VERSION "Nissan Sentra broadcast and body-control signals"

NS_ :

BS_:

BU_: BCM XXX Vector__XXX

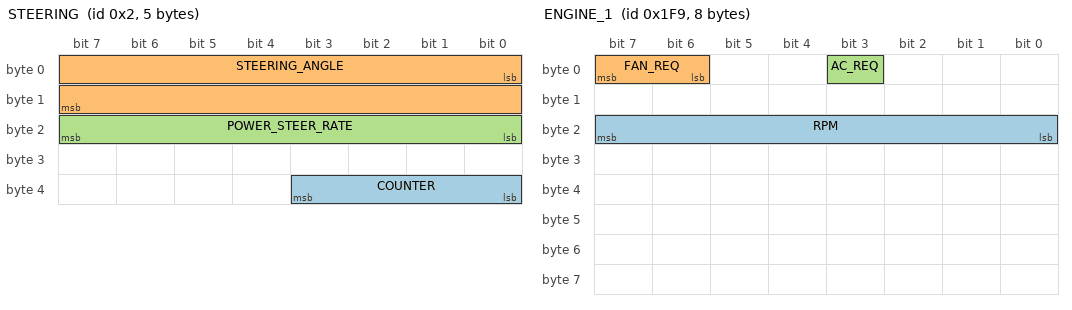
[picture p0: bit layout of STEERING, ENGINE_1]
BO_ 2 STEERING: 5 XXX
 SG_ COUNTER : 35|4@0+ (1,0) [0|255] "" XXX
 SG_ STEERING_ANGLE : 0|16@1- (0.1,0) [0|65535] "deg" XXX
 SG_ POWER_STEER_RATE : 23|8@0+ (1,0) [0|255] "" XXX

BO_ 505 ENGINE_1: 8 XXX
 SG_ RPM : 16|8@1+ (34.8837,0) [0|45000] "R/min" XXX
 SG_ FAN_REQ : 6|2@1+ (1,0) [0|3] "" XXX
 SG_ AC_REQ : 3|1@1+ (1,0) [0|1] "" XXX

BO_ 561 ENGINE_2: 8 XXX
 SG_ PEDAL_POSITION_ENGINE_2 : 16|8@1+ (0.5,0) [0|200] "%" XXX

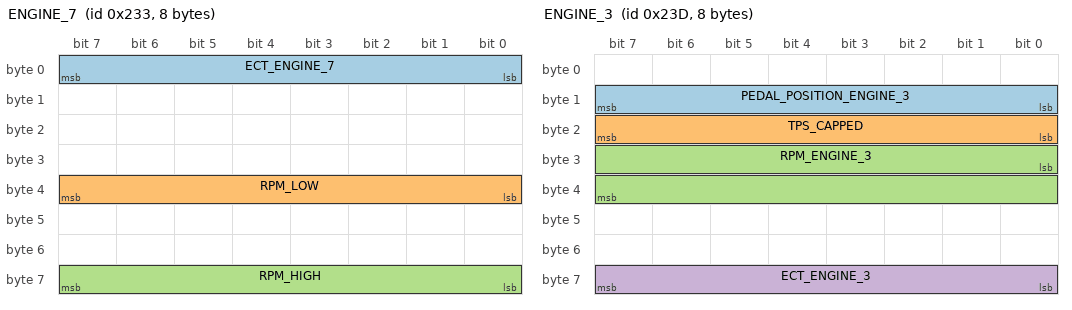
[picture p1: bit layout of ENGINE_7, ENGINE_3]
BO_ 563 ENGINE_7: 8 XXX
 SG_ ECT_ENGINE_7 : 0|8@1+ (0.366666,0) [0|255] "C" XXX
 SG_ RPM_LOW : 32|8@1+ (3.15,0) [0|45000] "R/min" XXX
 SG_ RPM_HIGH : 56|8@1+ (3.15,0) [0|45000] "R/min" XXX

BO_ 573 ENGINE_3: 8 XXX
 SG_ PEDAL_POSITION_ENGINE_3 : 8|8@1+ (0.392,0) [0|255] "%" XXX
 SG_ TPS_CAPPED : 16|8@1+ (0.392,0) [0|255] "%" XXX
 SG_ RPM_ENGINE_3 : 24|16@1+ (3.15,0) [0|45000] "R/min" XXX
 SG_ ECT_ENGINE_3 : 56|8@1+ (0.366666,0) [0|255] "C" XXX

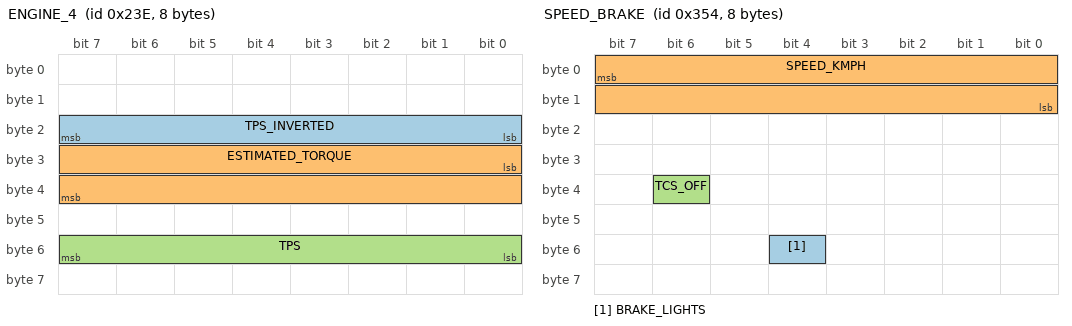
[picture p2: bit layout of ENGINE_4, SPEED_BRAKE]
BO_ 574 ENGINE_4: 8 XXX
 SG_ TPS_INVERTED : 16|8@1+ (0.392,0) [0|255] "%" XXX
 SG_ ESTIMATED_TORQUE : 24|16@1+ (0.1,0) [0|45000] "Nm" XXX
 SG_ TPS : 48|8@1+ (0.392,0) [0|255] "%" XXX

BO_ 595 TCU_1: 8 XXX
 SG_ SHAFT_1_SPEED : 32|16@1+ (1,0) [0|45000] "r/min" XXX
 SG_ SHAFT_2_SPEED : 48|16@1+ (1,0) [0|45000] "r/min" XXX

BO_ 640 SPEED: 8 XXX
 SG_ SPEED : 32|16@1+ (0.01,0) [0|45000] "km/h" XXX

BO_ 644 ABS_1: 8 XXX
 SG_ WHEEL_1_SPEED : 0|16@1+ (0.01,0) [0|45000] "km/h" XXX
 SG_ WHEEL_2_SPEED : 15|16@1+ (0.01,0) [0|45000] "km/h" XXX

BO_ 645 ABS_2: 8 XXX
 SG_ WHEEL_3_SPEED : 0|16@1+ (0.01,0) [0|45000] "km/h" XXX
 SG_ WHEEL_4_SPEED : 15|16@1+ (0.01,0) [0|45000] "km/h" XXX

BO_ 852 SPEED_BRAKE: 8 XXX
 SG_ BRAKE_LIGHTS : 52|1@0+ (1,0) [0|1] "" XXX
 SG_ SPEED_KMPH : 7|16@0+ (0.010176,0) [0|101348.4544] "km/h" XXX
 SG_ TCS_OFF : 38|1@0+ (1,0) [0|1] "" XXX

BO_ 861 BCM: 8 XXX

BO_ 1361 ENGINE_5: 8 XXX
 SG_ ECT : 0|8@1+ (1,-45) [-45|150] "C" XXX

BO_ 1408 ENGINE_6: 8 XXX
 SG_ RPM_ENGINE_6 : 7|16@0+ (1.5,0) [0|65535] "" XXX
 SG_ OIL_TEMP : 32|8@1+ (1,-40) [-40|150] "C" XXX

BO_ 1477 MILEAGE: 8 XXX

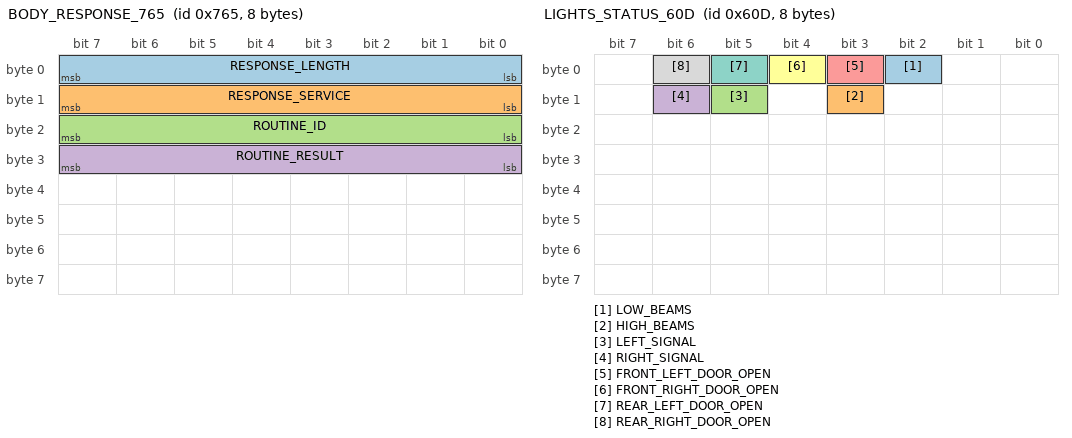
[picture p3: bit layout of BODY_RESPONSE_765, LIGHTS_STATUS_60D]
BO_ 1893 BODY_RESPONSE_765: 8 BCM
 SG_ RESPONSE_LENGTH : 0|8@1+ (1,0) [0|8] "" Vector__XXX
 SG_ RESPONSE_SERVICE : 8|8@1+ (1,0) [0|255] "" Vector__XXX
 SG_ ROUTINE_ID : 16|8@1+ (1,0) [0|255] "" Vector__XXX
 SG_ ROUTINE_RESULT : 24|8@1+ (1,0) [0|255] "" Vector__XXX

BO_ 1549 LIGHTS_STATUS_60D: 8 BCM
 SG_ LOW_BEAMS : 2|1@1+ (1,0) [0|1] "" Vector__XXX
 SG_ HIGH_BEAMS : 11|1@1+ (1,0) [0|1] "" Vector__XXX
 SG_ LEFT_SIGNAL : 13|1@1+ (1,0) [0|1] "" Vector__XXX
 SG_ RIGHT_SIGNAL : 14|1@1+ (1,0) [0|1] "" Vector__XXX
 SG_ FRONT_LEFT_DOOR_OPEN : 3|1@1+ (1,0) [0|1] "" Vector__XXX
 SG_ FRONT_RIGHT_DOOR_OPEN : 4|1@1+ (1,0) [0|1] "" Vector__XXX
 SG_ REAR_LEFT_DOOR_OPEN : 5|1@1+ (1,0) [0|1] "" Vector__XXX
 SG_ REAR_RIGHT_DOOR_OPEN : 6|1@1+ (1,0) [0|1] "" Vector__XXX

VAL_ 1549 LOW_BEAMS 0 "off" 1 "on";
VAL_ 1549 HIGH_BEAMS 0 "off" 1 "on";
VAL_ 1549 LEFT_SIGNAL 0 "off" 1 "on";
VAL_ 1549 RIGHT_SIGNAL 0 "off" 1 "on";
VAL_ 1549 FRONT_LEFT_DOOR_OPEN 0 "closed" 1 "open";
VAL_ 1549 FRONT_RIGHT_DOOR_OPEN 0 "closed" 1 "open";
VAL_ 1549 REAR_LEFT_DOOR_OPEN 0 "closed" 1 "open";
VAL_ 1549 REAR_RIGHT_DOOR_OPEN 0 "closed" 1 "open";
VAL_ 852 BRAKE_LIGHTS 0 "off" 1 "on";
VAL_ 852 TCS_OFF 0 "off" 1 "on";
VAL_ 505 AC_REQ 0 "off" 1 "on";

CM_ BO_ 1549 "CAN ID 0x60D from Nissan Sentra 2010 notes. Light-related signals plus door ajar bits included because they share the same frame.";
CM_ SG_ 1549 LOW_BEAMS "From nissan.md: A.2-A.3 => low beams are on when the high bit is set; this treats both 0b10 low beams and 0b11 fog lights as LOW_BEAMS=1.";
CM_ SG_ 1549 HIGH_BEAMS "From nissan.md: B.4 => 0 high beams off, 1 high beams on.";
CM_ SG_ 1549 LEFT_SIGNAL "From nissan.md: B.6 => 0 left signal off, 1 left signal on.";
CM_ SG_ 1549 RIGHT_SIGNAL "From nissan.md: B.7 => 0 right signal off, 1 right signal on.";
CM_ SG_ 1549 FRONT_LEFT_DOOR_OPEN "From nissan.md: A.4 => 0 closed, 1 open.";
CM_ SG_ 1549 FRONT_RIGHT_DOOR_OPEN "From nissan.md: A.5 => 0 closed, 1 open.";
CM_ SG_ 1549 REAR_LEFT_DOOR_OPEN "From nissan.md: A.6 => 0 closed, 1 open.";
CM_ SG_ 1549 REAR_RIGHT_DOOR_OPEN "From nissan.md: A.7 => 0 closed, 1 open.";
CM_ BO_ 1893 "CAN ID 0x765 positive responses to body-control requests sent on 0x745.";
